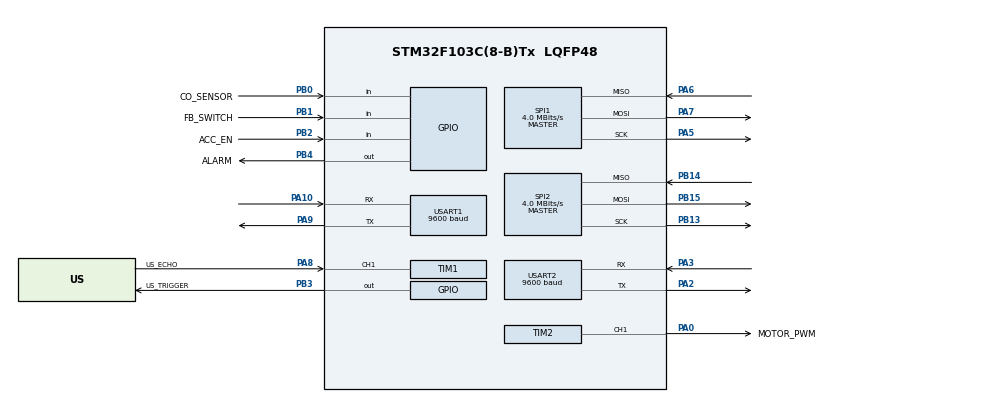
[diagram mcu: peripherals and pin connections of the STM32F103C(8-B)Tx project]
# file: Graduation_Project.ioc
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Mcu.Family=STM32F1
Mcu.Name=STM32F103C(8-B)Tx
Mcu.Package=LQFP48
NVIC.PriorityGroup=NVIC_PRIORITYGROUP_4
PA0-WKUP.GPIO_Label=MOTOR_PWM
PA0-WKUP.Signal=S_TIM2_CH1_ETR
PA10.Mode=Asynchronous
PA10.Signal=USART1_RX
PA2.Mode=Asynchronous
PA2.Signal=USART2_TX
PA3.Mode=Asynchronous
PA3.Signal=USART2_RX
PA5.Mode=Full_Duplex_Master
PA5.Signal=SPI1_SCK
PA6.Mode=Full_Duplex_Master
PA6.Signal=SPI1_MISO
PA7.Mode=Full_Duplex_Master
PA7.Signal=SPI1_MOSI
PA8.GPIO_Label=US_ECHO
PA8.Signal=S_TIM1_CH1
PA9.Mode=Asynchronous
PA9.Signal=USART1_TX
PB0.GPIO_Label=CO_SENSOR
PB0.Signal=GPIO_Input
PB1.GPIO_Label=FB_SWITCH
PB1.Signal=GPIO_Input
PB13.Mode=Full_Duplex_Master
PB13.Signal=SPI2_SCK
PB14.Mode=Full_Duplex_Master
PB14.Signal=SPI2_MISO
PB15.Mode=Full_Duplex_Master
PB15.Signal=SPI2_MOSI
PB2.GPIO_Label=ACC_EN
PB2.Signal=GPIO_Input
PB3.GPIO_Label=US_TRIGGER
PB3.Signal=GPIO_Output
PB4.GPIO_Label=ALARM
PB4.Signal=GPIO_Output
PD0-OSC_IN.Mode=HSE-External-Oscillator
PD0-OSC_IN.Signal=RCC_OSC_IN
PD1-OSC_OUT.Mode=HSE-External-Oscillator
PD1-OSC_OUT.Signal=RCC_OSC_OUT
ProjectManager.HeapSize=0x200
ProjectManager.StackSize=0x400
ProjectManager.TargetToolchain=STM32CubeIDE
RCC.APB1Freq_Value=8000000
RCC.APB2Freq_Value=8000000
SH.S_TIM1_CH1.0=TIM1_CH1,Input_Capture1_from_TI1
SH.S_TIM2_CH1_ETR.0=TIM2_CH1,PWM Generation1 CH1
SPI1.CalculateBaudRate=4.0 MBits/s
SPI1.Direction=SPI_DIRECTION_2LINES
SPI1.Mode=SPI_MODE_MASTER
SPI1.VirtualType=VM_MASTER
SPI2.CalculateBaudRate=4.0 MBits/s
SPI2.Direction=SPI_DIRECTION_2LINES
SPI2.Mode=SPI_MODE_MASTER
SPI2.VirtualType=VM_MASTER
TIM1.Channel-Input_Capture1_from_TI1=TIM_CHANNEL_1
TIM2.Channel-PWM\ Generation1\ CH1=TIM_CHANNEL_1
USART1.BaudRate=9600
USART1.VirtualMode=VM_ASYNC
USART2.BaudRate=9600
USART2.VirtualMode=VM_ASYNC
VP_SYS_VS_ND.Mode=No_Debug
board=custom

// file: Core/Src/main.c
/* USER CODE BEGIN Header */
/**
  ******************************************************************************
  * @file           : main.c
  * @brief          : Main program body
  ******************************************************************************
  * @attention
  *
  * Copyright (c) 2022 STMicroelectronics.
  * All rights reserved.
  *
  * This software is licensed under terms that can be found in the LICENSE file
  * in the root directory of this software component.
  * If no LICENSE file comes with this software, it is provided AS-IS.
  *
  ******************************************************************************
  */
/* USER CODE END Header */
#include "main.h"

SPI_HandleTypeDef hspi1;
SPI_HandleTypeDef hspi2;

TIM_HandleTypeDef htim1;
TIM_HandleTypeDef htim2;

UART_HandleTypeDef huart1;
UART_HandleTypeDef huart2;

void SystemClock_Config(void);
static void MX_GPIO_Init(void);
static void MX_SPI1_Init(void);
static void MX_SPI2_Init(void);
static void MX_TIM1_Init(void);
static void MX_TIM2_Init(void);
static void MX_USART1_UART_Init(void);
static void MX_USART2_UART_Init(void);

int main(void)
{
  /* USER CODE BEGIN 1 */
	//Hello World
  /* USER CODE END 1 */

  /* MCU Configuration--------------------------------------------------------*/

  /* Reset of all peripherals, Initializes the Flash interface and the Systick. */
  HAL_Init();

  /* Configure the system clock */
  SystemClock_Config();

  /* Initialize all configured peripherals */
  MX_GPIO_Init();
  MX_SPI1_Init();
  MX_SPI2_Init();
  MX_TIM1_Init();
  MX_TIM2_Init();
  MX_USART1_UART_Init();
  MX_USART2_UART_Init();

  /* Infinite loop */
  while (1)
  {

  }
}

void SystemClock_Config(void)
{
  RCC_OscInitTypeDef RCC_OscInitStruct = {0};
  RCC_ClkInitTypeDef RCC_ClkInitStruct = {0};

  /** Initializes the RCC Oscillators according to the specified parameters
  * in the RCC_OscInitTypeDef structure.
  */
  RCC_OscInitStruct.OscillatorType = RCC_OSCILLATORTYPE_HSI;
  RCC_OscInitStruct.HSIState = RCC_HSI_ON;
  RCC_OscInitStruct.HSICalibrationValue = RCC_HSICALIBRATION_DEFAULT;
  RCC_OscInitStruct.PLL.PLLState = RCC_PLL_NONE;
  if (HAL_RCC_OscConfig(&RCC_OscInitStruct) != HAL_OK)
  {
    Error_Handler();
  }
  /** Initializes the CPU, AHB and APB buses clocks
  */
  RCC_ClkInitStruct.ClockType = RCC_CLOCKTYPE_HCLK|RCC_CLOCKTYPE_SYSCLK
                              |RCC_CLOCKTYPE_PCLK1|RCC_CLOCKTYPE_PCLK2;
  RCC_ClkInitStruct.SYSCLKSource = RCC_SYSCLKSOURCE_HSI;
  RCC_ClkInitStruct.AHBCLKDivider = RCC_SYSCLK_DIV1;
  RCC_ClkInitStruct.APB1CLKDivider = RCC_HCLK_DIV1;
  RCC_ClkInitStruct.APB2CLKDivider = RCC_HCLK_DIV1;

  if (HAL_RCC_ClockConfig(&RCC_ClkInitStruct, FLASH_LATENCY_0) != HAL_OK)
  {
    Error_Handler();
  }
}

static void MX_SPI1_Init(void)
{

  /* SPI1 parameter configuration*/
  hspi1.Instance = SPI1;
  hspi1.Init.Mode = SPI_MODE_MASTER;
  hspi1.Init.Direction = SPI_DIRECTION_2LINES;
  hspi1.Init.DataSize = SPI_DATASIZE_8BIT;
  hspi1.Init.CLKPolarity = SPI_POLARITY_LOW;
  hspi1.Init.CLKPhase = SPI_PHASE_1EDGE;
  hspi1.Init.NSS = SPI_NSS_SOFT;
  hspi1.Init.BaudRatePrescaler = SPI_BAUDRATEPRESCALER_2;
  hspi1.Init.FirstBit = SPI_FIRSTBIT_MSB;
  hspi1.Init.TIMode = SPI_TIMODE_DISABLE;
  hspi1.Init.CRCCalculation = SPI_CRCCALCULATION_DISABLE;
  hspi1.Init.CRCPolynomial = 10;
  if (HAL_SPI_Init(&hspi1) != HAL_OK)
  {
    Error_Handler();
  }

}

static void MX_SPI2_Init(void)
{

  /* SPI2 parameter configuration*/
  hspi2.Instance = SPI2;
  hspi2.Init.Mode = SPI_MODE_MASTER;
  hspi2.Init.Direction = SPI_DIRECTION_2LINES;
  hspi2.Init.DataSize = SPI_DATASIZE_8BIT;
  hspi2.Init.CLKPolarity = SPI_POLARITY_LOW;
  hspi2.Init.CLKPhase = SPI_PHASE_1EDGE;
  hspi2.Init.NSS = SPI_NSS_SOFT;
  hspi2.Init.BaudRatePrescaler = SPI_BAUDRATEPRESCALER_2;
  hspi2.Init.FirstBit = SPI_FIRSTBIT_MSB;
  hspi2.Init.TIMode = SPI_TIMODE_DISABLE;
  hspi2.Init.CRCCalculation = SPI_CRCCALCULATION_DISABLE;
  hspi2.Init.CRCPolynomial = 10;
  if (HAL_SPI_Init(&hspi2) != HAL_OK)
  {
    Error_Handler();
  }

}

static void MX_TIM1_Init(void)
{

  TIM_MasterConfigTypeDef sMasterConfig = {0};
  TIM_IC_InitTypeDef sConfigIC = {0};

  htim1.Instance = TIM1;
  htim1.Init.Prescaler = 0;
  htim1.Init.CounterMode = TIM_COUNTERMODE_UP;
  htim1.Init.Period = 65535;
  htim1.Init.ClockDivision = TIM_CLOCKDIVISION_DIV1;
  htim1.Init.RepetitionCounter = 0;
  htim1.Init.AutoReloadPreload = TIM_AUTORELOAD_PRELOAD_DISABLE;
  if (HAL_TIM_IC_Init(&htim1) != HAL_OK)
  {
    Error_Handler();
  }
  sMasterConfig.MasterOutputTrigger = TIM_TRGO_RESET;
  sMasterConfig.MasterSlaveMode = TIM_MASTERSLAVEMODE_DISABLE;
  if (HAL_TIMEx_MasterConfigSynchronization(&htim1, &sMasterConfig) != HAL_OK)
  {
    Error_Handler();
  }
  sConfigIC.ICPolarity = TIM_INPUTCHANNELPOLARITY_RISING;
  sConfigIC.ICSelection = TIM_ICSELECTION_DIRECTTI;
  sConfigIC.ICPrescaler = TIM_ICPSC_DIV1;
  sConfigIC.ICFilter = 0;
  if (HAL_TIM_IC_ConfigChannel(&htim1, &sConfigIC, TIM_CHANNEL_1) != HAL_OK)
  {
    Error_Handler();
  }

}

static void MX_TIM2_Init(void)
{

  TIM_MasterConfigTypeDef sMasterConfig = {0};
  TIM_OC_InitTypeDef sConfigOC = {0};

  htim2.Instance = TIM2;
  htim2.Init.Prescaler = 0;
  htim2.Init.CounterMode = TIM_COUNTERMODE_UP;
  htim2.Init.Period = 65535;
  htim2.Init.ClockDivision = TIM_CLOCKDIVISION_DIV1;
  htim2.Init.AutoReloadPreload = TIM_AUTORELOAD_PRELOAD_DISABLE;
  if (HAL_TIM_PWM_Init(&htim2) != HAL_OK)
  {
    Error_Handler();
  }
  sMasterConfig.MasterOutputTrigger = TIM_TRGO_RESET;
  sMasterConfig.MasterSlaveMode = TIM_MASTERSLAVEMODE_DISABLE;
  if (HAL_TIMEx_MasterConfigSynchronization(&htim2, &sMasterConfig) != HAL_OK)
  {
    Error_Handler();
  }
  sConfigOC.OCMode = TIM_OCMODE_PWM1;
  sConfigOC.Pulse = 0;
  sConfigOC.OCPolarity = TIM_OCPOLARITY_HIGH;
  sConfigOC.OCFastMode = TIM_OCFAST_DISABLE;
  if (HAL_TIM_PWM_ConfigChannel(&htim2, &sConfigOC, TIM_CHANNEL_1) != HAL_OK)
  {
    Error_Handler();
  }
  HAL_TIM_MspPostInit(&htim2);

}

static void MX_USART1_UART_Init(void)
{

  huart1.Instance = USART1;
  huart1.Init.BaudRate = 9600;
  huart1.Init.WordLength = UART_WORDLENGTH_8B;
  huart1.Init.StopBits = UART_STOPBITS_1;
  huart1.Init.Parity = UART_PARITY_NONE;
  huart1.Init.Mode = UART_MODE_TX_RX;
  huart1.Init.HwFlowCtl = UART_HWCONTROL_NONE;
  huart1.Init.OverSampling = UART_OVERSAMPLING_16;
  if (HAL_UART_Init(&huart1) != HAL_OK)
  {
    Error_Handler();
  }

}

static void MX_USART2_UART_Init(void)
{

  huart2.Instance = USART2;
  huart2.Init.BaudRate = 9600;
  huart2.Init.WordLength = UART_WORDLENGTH_8B;
  huart2.Init.StopBits = UART_STOPBITS_1;
  huart2.Init.Parity = UART_PARITY_NONE;
  huart2.Init.Mode = UART_MODE_TX_RX;
  huart2.Init.HwFlowCtl = UART_HWCONTROL_NONE;
  huart2.Init.OverSampling = UART_OVERSAMPLING_16;
  if (HAL_UART_Init(&huart2) != HAL_OK)
  {
    Error_Handler();
  }

}

static void MX_GPIO_Init(void)
{
  GPIO_InitTypeDef GPIO_InitStruct = {0};

  /* GPIO Ports Clock Enable */
  __HAL_RCC_GPIOD_CLK_ENABLE();
  __HAL_RCC_GPIOA_CLK_ENABLE();
  __HAL_RCC_GPIOB_CLK_ENABLE();

  /*Configure GPIO pin Output Level */
  HAL_GPIO_WritePin(GPIOB, US_TRIGGER_Pin|ALARM_Pin, GPIO_PIN_RESET);

  /*Configure GPIO pins : CO_SENSOR_Pin FB_SWITCH_Pin ACC_EN_Pin */
  GPIO_InitStruct.Pin = CO_SENSOR_Pin|FB_SWITCH_Pin|ACC_EN_Pin;
  GPIO_InitStruct.Mode = GPIO_MODE_INPUT;
  GPIO_InitStruct.Pull = GPIO_NOPULL;
  HAL_GPIO_Init(GPIOB, &GPIO_InitStruct);

  /*Configure GPIO pins : US_TRIGGER_Pin ALARM_Pin */
  GPIO_InitStruct.Pin = US_TRIGGER_Pin|ALARM_Pin;
  GPIO_InitStruct.Mode = GPIO_MODE_OUTPUT_PP;
  GPIO_InitStruct.Pull = GPIO_NOPULL;
  GPIO_InitStruct.Speed = GPIO_SPEED_FREQ_LOW;
  HAL_GPIO_Init(GPIOB, &GPIO_InitStruct);

}

void Error_Handler(void)
{
  __disable_irq();
  while (1)
  {
  }
}
